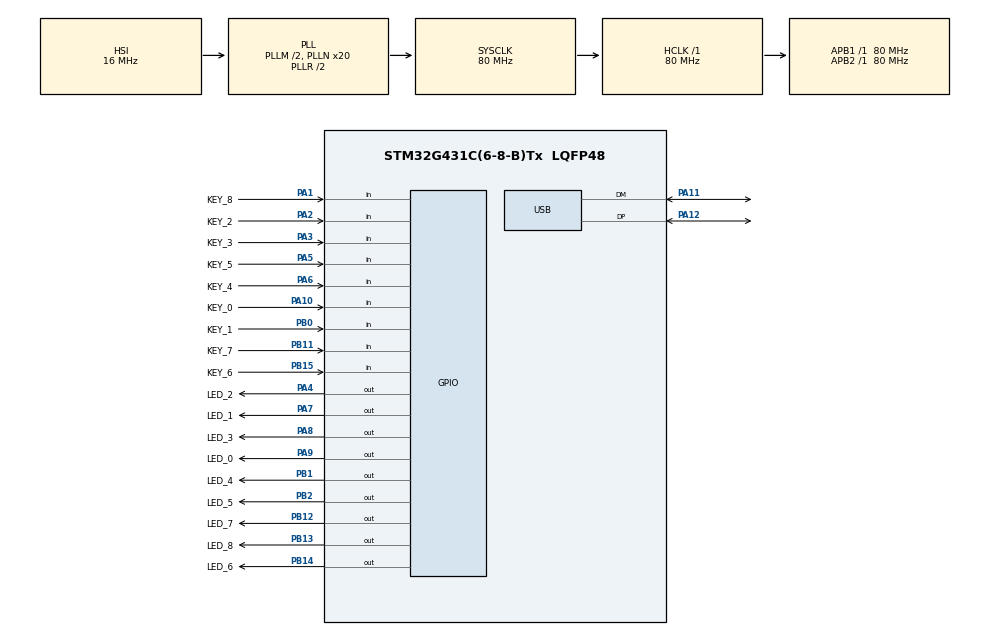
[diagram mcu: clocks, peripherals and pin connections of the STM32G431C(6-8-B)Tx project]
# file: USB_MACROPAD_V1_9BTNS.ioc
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Mcu.Family=STM32G4
Mcu.Name=STM32G431C(6-8-B)Tx
Mcu.Package=LQFP48
NVIC.PriorityGroup=NVIC_PRIORITYGROUP_4
NVIC.USB_LP_IRQn=true\:0\:0\:false\:false\:true\:true\:true\:true
PA1.GPIO_Label=KEY_8
PA1.GPIO_PuPd=GPIO_PULLUP
PA1.Signal=GPIO_Input
PA10.GPIO_Label=KEY_0
PA10.GPIO_PuPd=GPIO_PULLUP
PA10.Signal=GPIO_Input
PA11.Mode=Device
PA11.Signal=USB_DM
PA12.Mode=Device
PA12.Signal=USB_DP
PA13.Mode=Trace_Asynchronous_SW
PA13.Signal=SYS_JTMS-SWDIO
PA14.Mode=Trace_Asynchronous_SW
PA14.Signal=SYS_JTCK-SWCLK
PA2.GPIO_Label=KEY_2
PA2.GPIO_PuPd=GPIO_PULLUP
PA2.Signal=GPIO_Input
PA3.GPIO_Label=KEY_3
PA3.GPIO_PuPd=GPIO_PULLUP
PA3.Signal=GPIO_Input
PA4.GPIO_Label=LED_2
PA4.Signal=GPIO_Output
PA5.GPIO_Label=KEY_5
PA5.GPIO_PuPd=GPIO_PULLUP
PA5.Signal=GPIO_Input
PA6.GPIO_Label=KEY_4
PA6.GPIO_PuPd=GPIO_PULLUP
PA6.Signal=GPIO_Input
PA7.GPIO_Label=LED_1
PA7.Signal=GPIO_Output
PA8.GPIO_Label=LED_3
PA8.Signal=GPIO_Output
PA9.GPIO_Label=LED_0
PA9.Signal=GPIO_Output
PB0.GPIO_Label=KEY_1
PB0.GPIO_PuPd=GPIO_PULLUP
PB0.Signal=GPIO_Input
PB1.GPIO_Label=LED_4
PB1.Signal=GPIO_Output
PB11.GPIO_Label=KEY_7
PB11.GPIO_PuPd=GPIO_PULLUP
PB11.Signal=GPIO_Input
PB12.GPIO_Label=LED_7
PB12.Signal=GPIO_Output
PB13.GPIO_Label=LED_8
PB13.Signal=GPIO_Output
PB14.GPIO_Label=LED_6
PB14.Signal=GPIO_Output
PB15.GPIO_Label=KEY_6
PB15.GPIO_PuPd=GPIO_PULLUP
PB15.Signal=GPIO_Input
PB2.GPIO_Label=LED_5
PB2.Signal=GPIO_Output
PB3.Mode=Trace_Asynchronous_SW
PB3.Signal=SYS_JTDO-SWO
ProjectManager.HeapSize=0x200
ProjectManager.StackSize=0x400
ProjectManager.TargetToolchain=STM32CubeIDE
RCC.ADC12Freq_Value=80000000
RCC.AHBFreq_Value=80000000
RCC.APB1Freq_Value=80000000
RCC.APB1TimFreq_Value=80000000
RCC.APB2Freq_Value=80000000
RCC.APB2TimFreq_Value=80000000
RCC.CK48CLockSelection=RCC_USBCLKSOURCE_HSI48
RCC.CortexFreq_Value=80000000
RCC.EXTERNAL_CLOCK_VALUE=12288000
RCC.HCLKFreq_Value=80000000
RCC.HSE_VALUE=8000000
RCC.HSI48_VALUE=48000000
RCC.HSI_VALUE=16000000
RCC.LSE_VALUE=32768
RCC.PLLM=RCC_PLLM_DIV2
RCC.PLLN=20
RCC.SYSCLKFreq_VALUE=80000000
RCC.SYSCLKSource=RCC_SYSCLKSOURCE_PLLCLK
RCC.USBFreq_Value=48000000
RCC.VCOOutputFreq_Value=160000000
USB_DEVICE.CLASS_NAME_FS=CUSTOM_HID
USB_DEVICE.MANUFACTURER_STRING=Cogman
USB_DEVICE.PRODUCT_STRING_CUSTOMHID_FS=Cogman Macropad V1
USB_DEVICE.USBD_CUSTOMHID_OUTREPORT_BUF_SIZE=64
USB_DEVICE.USBD_CUSTOM_HID_REPORT_DESC_SIZE=40
USB_DEVICE.USBD_SELF_POWERED=0
USB_DEVICE.VirtualMode=CustomHid
USB_DEVICE.VirtualModeFS=Custom_Hid_FS
VP_SYS_VS_DBSignals.Mode=DisableDeadBatterySignals
VP_USB_DEVICE_VS_USB_DEVICE_CUSTOM_HID_FS.Mode=CUSTOM_HID_FS
board=custom

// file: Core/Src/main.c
/* USER CODE BEGIN Header */
/**
  ******************************************************************************
  * @file           : main.c
  * @brief          : Main program body
  ******************************************************************************
  * @attention
  *
  * Copyright (c) 2026 STMicroelectronics.
  * All rights reserved.
  *
  * This software is licensed under terms that can be found in the LICENSE file
  * in the root directory of this software component.
  * If no LICENSE file comes with this software, it is provided AS-IS.
  *
  ******************************************************************************
  */
/* USER CODE END Header */
#include "main.h"
#include "usb_device.h"
#include "usbd_customhid.h"
/* USER CODE BEGIN Includes */
#include <stdio.h>
/* USER CODE END Includes */

void SystemClock_Config(void);
static void MX_GPIO_Init(void);

/* USER CODE BEGIN 0 */

void SWO_Print(const char *text)
{
    while (*text)
    {
        ITM_SendChar(*text++);
    }
}

/* USER CODE END 0 */

int main(void)
{

  /* MCU Configuration--------------------------------------------------------*/

  /* Reset of all peripherals, Initializes the Flash interface and the Systick. */
  HAL_Init();

  /* Configure the system clock */
  SystemClock_Config();

  /* Initialize all configured peripherals */
  MX_GPIO_Init();
  MX_USB_Device_Init();
  /* USER CODE BEGIN 2 */
  /*Initialize button reading*/
  bttnsInit();
  /* USER CODE END 2 */

  /* Infinite loop */
  /* USER CODE BEGIN WHILE */
  uint8_t update;
  uint8_t txBuffer[USB_QUEUE_ELEM_SIZE];

  while (1)
  {
    /* USER CODE END WHILE */
	/*update button states*/
	update = bttnsUpdate();

	/*If the button state changed*/
	if(update){

		USB_Enqueue_Report(bttnsRead(txBuffer));
	}
	USB_update();
  }
}

void SystemClock_Config(void)
{
  RCC_OscInitTypeDef RCC_OscInitStruct = {0};
  RCC_ClkInitTypeDef RCC_ClkInitStruct = {0};

  /** Configure the main internal regulator output voltage
  */
  HAL_PWREx_ControlVoltageScaling(PWR_REGULATOR_VOLTAGE_SCALE1);

  /** Initializes the RCC Oscillators according to the specified parameters
  * in the RCC_OscInitTypeDef structure.
  */
  RCC_OscInitStruct.OscillatorType = RCC_OSCILLATORTYPE_HSI|RCC_OSCILLATORTYPE_HSI48;
  RCC_OscInitStruct.HSIState = RCC_HSI_ON;
  RCC_OscInitStruct.HSICalibrationValue = RCC_HSICALIBRATION_DEFAULT;
  RCC_OscInitStruct.HSI48State = RCC_HSI48_ON;
  RCC_OscInitStruct.PLL.PLLState = RCC_PLL_ON;
  RCC_OscInitStruct.PLL.PLLSource = RCC_PLLSOURCE_HSI;
  RCC_OscInitStruct.PLL.PLLM = RCC_PLLM_DIV2;
  RCC_OscInitStruct.PLL.PLLN = 20;
  RCC_OscInitStruct.PLL.PLLP = RCC_PLLP_DIV2;
  RCC_OscInitStruct.PLL.PLLQ = RCC_PLLQ_DIV2;
  RCC_OscInitStruct.PLL.PLLR = RCC_PLLR_DIV2;
  if (HAL_RCC_OscConfig(&RCC_OscInitStruct) != HAL_OK)
  {
    Error_Handler();
  }

  /** Initializes the CPU, AHB and APB buses clocks
  */
  RCC_ClkInitStruct.ClockType = RCC_CLOCKTYPE_HCLK|RCC_CLOCKTYPE_SYSCLK
                              |RCC_CLOCKTYPE_PCLK1|RCC_CLOCKTYPE_PCLK2;
  RCC_ClkInitStruct.SYSCLKSource = RCC_SYSCLKSOURCE_PLLCLK;
  RCC_ClkInitStruct.AHBCLKDivider = RCC_SYSCLK_DIV1;
  RCC_ClkInitStruct.APB1CLKDivider = RCC_HCLK_DIV1;
  RCC_ClkInitStruct.APB2CLKDivider = RCC_HCLK_DIV1;

  if (HAL_RCC_ClockConfig(&RCC_ClkInitStruct, FLASH_LATENCY_2) != HAL_OK)
  {
    Error_Handler();
  }
}

static void MX_GPIO_Init(void)
{
  GPIO_InitTypeDef GPIO_InitStruct = {0};

  /* GPIO Ports Clock Enable */
  __HAL_RCC_GPIOA_CLK_ENABLE();
  __HAL_RCC_GPIOB_CLK_ENABLE();

  /*Configure GPIO pin Output Level */
  HAL_GPIO_WritePin(GPIOA, LED_2_Pin|LED_1_Pin|LED_3_Pin|LED_0_Pin, GPIO_PIN_RESET);

  /*Configure GPIO pin Output Level */
  HAL_GPIO_WritePin(GPIOB, LED_4_Pin|LED_5_Pin|LED_7_Pin|LED_8_Pin
                          |LED_6_Pin, GPIO_PIN_RESET);

  /*Configure GPIO pins : KEY_8_Pin KEY_2_Pin KEY_3_Pin KEY_5_Pin
                           KEY_4_Pin KEY_0_Pin */
  GPIO_InitStruct.Pin = KEY_8_Pin|KEY_2_Pin|KEY_3_Pin|KEY_5_Pin
                          |KEY_4_Pin|KEY_0_Pin;
  GPIO_InitStruct.Mode = GPIO_MODE_INPUT;
  GPIO_InitStruct.Pull = GPIO_PULLUP;
  HAL_GPIO_Init(GPIOA, &GPIO_InitStruct);

  /*Configure GPIO pins : LED_2_Pin LED_1_Pin LED_3_Pin LED_0_Pin */
  GPIO_InitStruct.Pin = LED_2_Pin|LED_1_Pin|LED_3_Pin|LED_0_Pin;
  GPIO_InitStruct.Mode = GPIO_MODE_OUTPUT_PP;
  GPIO_InitStruct.Pull = GPIO_NOPULL;
  GPIO_InitStruct.Speed = GPIO_SPEED_FREQ_LOW;
  HAL_GPIO_Init(GPIOA, &GPIO_InitStruct);

  /*Configure GPIO pins : KEY_1_Pin KEY_7_Pin KEY_6_Pin */
  GPIO_InitStruct.Pin = KEY_1_Pin|KEY_7_Pin|KEY_6_Pin;
  GPIO_InitStruct.Mode = GPIO_MODE_INPUT;
  GPIO_InitStruct.Pull = GPIO_PULLUP;
  HAL_GPIO_Init(GPIOB, &GPIO_InitStruct);

  /*Configure GPIO pins : LED_4_Pin LED_5_Pin LED_7_Pin LED_8_Pin
                           LED_6_Pin */
  GPIO_InitStruct.Pin = LED_4_Pin|LED_5_Pin|LED_7_Pin|LED_8_Pin
                          |LED_6_Pin;
  GPIO_InitStruct.Mode = GPIO_MODE_OUTPUT_PP;
  GPIO_InitStruct.Pull = GPIO_NOPULL;
  GPIO_InitStruct.Speed = GPIO_SPEED_FREQ_LOW;
  HAL_GPIO_Init(GPIOB, &GPIO_InitStruct);

}

void Error_Handler(void)
{
  __disable_irq();
  while (1)
  {
  }
}
